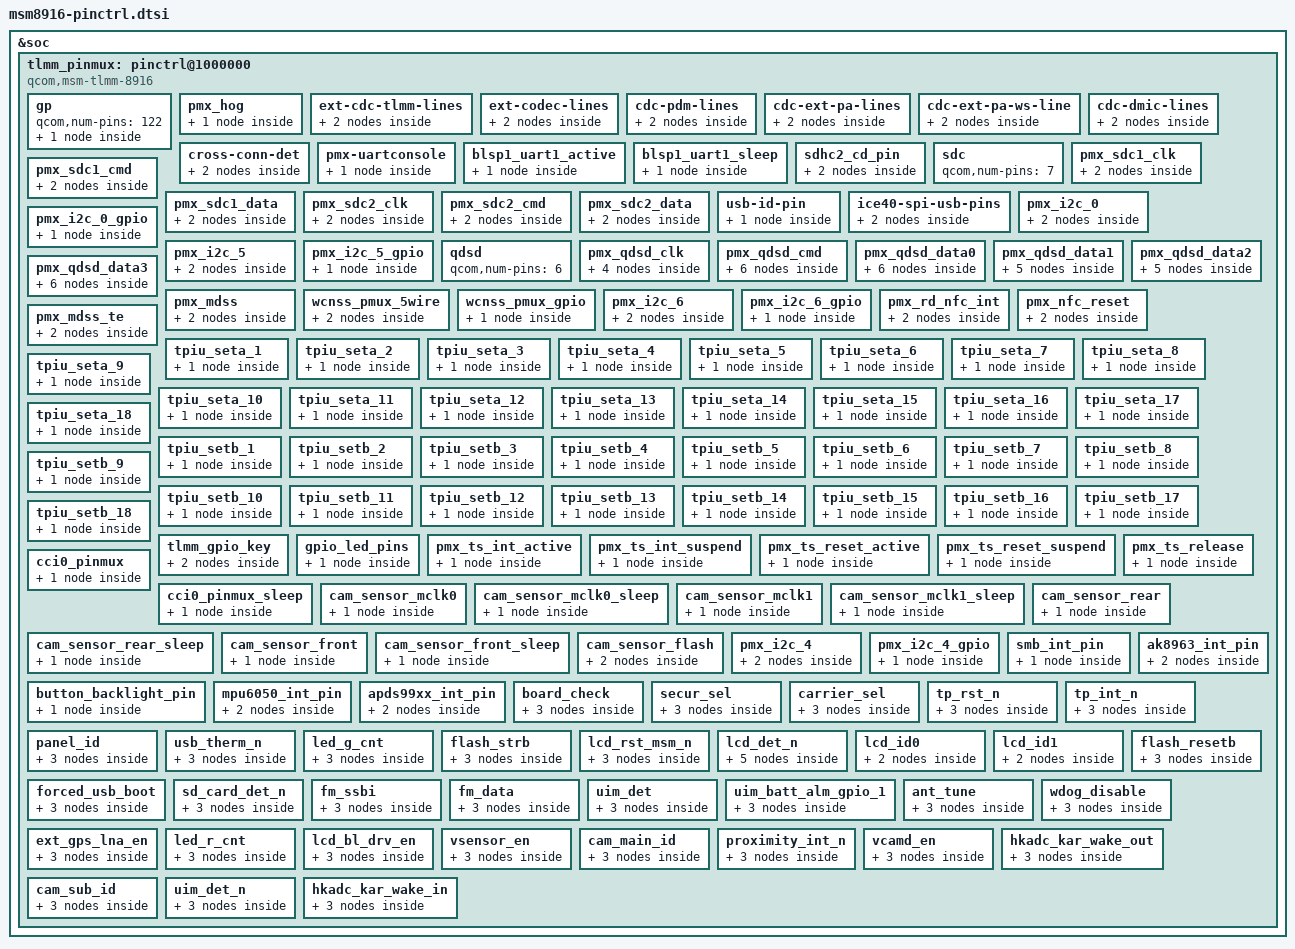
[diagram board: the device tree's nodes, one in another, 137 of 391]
/* Copyright (c) 2013-2014, The Linux Foundation. All rights reserved.
 *
 * This program is free software; you can redistribute it and/or modify
 * it under the terms of the GNU General Public License version 2 and
 * only version 2 as published by the Free Software Foundation.
 *
 * This program is distributed in the hope that it will be useful,
 * but WITHOUT ANY WARRANTY; without even the implied warranty of
 * MERCHANTABILITY or FITNESS FOR A PARTICULAR PURPOSE.  See the
 * GNU General Public License for more details.
 */
/*
 * This software is contributed or developed by KYOCERA Corporation.
 * (C) 2015 KYOCERA Corporation
 */

&soc {
	tlmm_pinmux: pinctrl@1000000 {
		compatible = "qcom,msm-tlmm-8916";
		reg = <0x1000000 0x300000>;
		interrupts = <0 208 0>;

		pinctrl-names = "default";
		pinctrl-0 = <&pmx_hog_default>;

		/*General purpose pins*/
		gp: gp {
			qcom,num-pins = <122>;
			#qcom,pin-cells = <1>;
			msm_gpio: msm_gpio {
				compatible = "qcom,msm-tlmm-gp";
				gpio-controller;
				#gpio-cells = <2>;
				interrupt-controller;
				#interrupt-cells = <2>;
				num_irqs = <122>;
			};
		};

		pmx_hog {
			qcom,pins = <&gp 2>, <&gp 3>, <&gp 10>, <&gp 11>, <&gp 34>,
						<&gp 49>, <&gp 50>, <&gp 51>, <&gp 52>,
						<&gp 53>, <&gp 54>, <&gp 55>, <&gp 56>,
						<&gp 74>, <&gp 75>, <&gp 76>, <&gp 77>, <&gp 78>,
						<&gp 81>, <&gp 82>, <&gp 83>, <&gp 84>, 
						<&gp 86>, <&gp 88>, <&gp 89>, <&gp 94>,
						<&gp 100>, <&gp 101>, <&gp 102>, <&gp 105>,
						<&gp 106>, <&gp 107>, <&gp 111>, <&gp 112>,
						<&gp 116>, <&gp 119>, <&gp 121>;
			qcom,num-grp-pins = <37>;
			qcom,pin-func = <0>;
			label = "hog";
			pmx_hog_default: pmx_hog_def {
				drive-strength = <2>;
				bias-pull-down;
				input-debounce = <0>;
			};
		};

		ext-cdc-tlmm-lines {
			qcom,pins = <&gp 116>, <&gp 112>, <&gp 117>,
						<&gp 118>, <&gp 119>;
			qcom,num-grp-pins = <5>;
			qcom,pin-func = <1>;
			label = "ext-cdc-tlmm-lines";
			ext_cdc_tlmm_lines_act: tlmm_lines_on {
				drive-strength = <8>;
				bias-pull-none;
			};
			ext_cdc_tlmm_lines_sus: tlmm_lines_off {
				drive-strength = <2>;
				bias-disable;
			};
		};

		ext-codec-lines {
			qcom,pins = <&gp 67>;
			qcom,num-grp-pins = <1>;
			qcom,pin-func = <0>;
			label = "ext-codec-lines";
			ext_codec_lines_act: lines_on {
				drive-strength = <8>;
				bias-disable;
				output-high;
			};
			ext_codec_lines_sus: lines_off {
				drive-strength = <2>;
				bias-disable;
			};
		};

		cdc-pdm-lines {
			qcom,pins = <&gp 63>, <&gp 64>, <&gp 65>,
					<&gp 66>, <&gp 67>, <&gp 68>;
			qcom,num-grp-pins = <6>;
			qcom,pin-func = <1>;
			label = "cdc-pdm-lines";
			cdc_pdm_lines_act: pdm_lines_on {
				drive-strength = <8>;
				bias-pull-none;
			};
			cdc_pdm_lines_sus: pdm_lines_off {
				drive-strength = <2>;
				bias-disable;
			};
		};

		cdc-ext-pa-lines {
			qcom,pins = <&gp 113>, <&gp 114>,
					<&gp 115>, <&gp 116>;
			qcom,num-grp-pins = <4>;
			qcom,pin-func = <1>;
			label = "cdc-ext-pa-lines";
			cdc_ext_pa_act: ext_pa_on {
				drive-strength = <8>;
				bias-pull-none;
			};
			cdc_ext_pa_sus: ext_pa_off {
				drive-strength = <2>;
				bias-disable;
			};
		};

		cdc-ext-pa-ws-line {
			qcom,pins = <&gp 110>;
			qcom,num-grp-pins = <1>;
			qcom,pin-func = <2>;
			label = "cdc-ext-pa-ws-line";
			cdc_ext_pa_ws_act: ext_pa_on {
				drive-strength = <8>;
				bias-pull-none;
			};
			cdc_ext_pa_ws_sus: ext_pa_off {
				drive-strength = <2>;
				bias-disable;
			};
		};

		cdc-dmic-lines {
			qcom,pins = <&gp 0>, <&gp 1>;
			qcom,num-grp-pins = <2>;
			qcom,pin-func = <4>;
			label = "cdc-dmic-lines";
			cdc_dmic_lines_act: dmic_lines_on {
				drive-strength = <8>;
			};
			cdc_dmic_lines_sus: dmic_lines_off {
				drive-strength = <2>;
				bias-disable;
			};
		};

		cross-conn-det {
			qcom,pins = <&gp 120>;
			qcom,num-grp-pins = <1>;
			qcom,pin-func = <0>;
			label = "cross-conn-det-sw";
			cross_conn_det_act: lines_on {
				drive-strength = <8>;
				output-low;
				bias-pull-down;
			};
			cross_conn_det_sus: lines_off {
				drive-strength = <2>;
				bias-disable;
			};
		};
		pmx-uartconsole {
			qcom,pins = <&gp 4>, <&gp 5>;
			qcom,num-grp-pins = <2>;
			qcom,pin-func = <2>;
			label = "uart-console";

		uart_console_sleep: uart-console {
				drive-strength = <2>;
				bias-pull-down;
			};
		};

		blsp1_uart1_active {
			qcom,pins = <&gp 0>, <&gp 1>, <&gp 2>, <&gp 3>;
			qcom,num-grp-pins = <4>;
			qcom,pin-func = <2>;
		        label = "blsp1_uart1_active";

			hsuart_active: default {
				drive-strength = <16>;
				bias-disable;
			};
		};

		blsp1_uart1_sleep {
			qcom,pins = <&gp 0>, <&gp 1>, <&gp 2>, <&gp 3>;
			qcom,num-grp-pins = <4>;
			qcom,pin-func = <0>;
		        label = "blsp1_uart1_sleep";

			hsuart_sleep: sleep {
				drive-strength = <2>;
				bias-disable;
			};
		};

		sdhc2_cd_pin {
			qcom,pins = <&gp 38>;
			qcom,num-grp-pins = <1>;
			qcom,pin-func = <0>;
			label = "cd-gpio";
			sdc2_cd_on: cd_on {
				drive-strength = <2>;
				bias-pull-up;
			};
			sdc2_cd_off: cd_off {
				drive-strength = <2>;
				bias-disable;
			};
		};

		/* SDC pin type */
		sdc: sdc {
			/* 0-2 for sdc1 4-6 for sdc2 */
			qcom,num-pins = <7>;
			/* Order of pins */
			/* SDC1: CLK -> 0, CMD -> 1, DATA -> 2 */
			/* SDC2: CLK -> 4, CMD -> 5, DATA -> 6 */
			#qcom,pin-cells = <1>;
		};

		pmx_sdc1_clk {
			qcom,pins = <&sdc 0>;
			qcom,num-grp-pins = <1>;
			label = "sdc1-clk";
			sdc1_clk_on: clk_on {
				bias-disable; /* NO pull */
				drive-strength = <16>; /* 16 MA */
			};
			sdc1_clk_off: clk_off {
				bias-disable; /* NO pull */
				drive-strength = <2>; /* 2 MA */
			};
		};

		pmx_sdc1_cmd {
			qcom,pins = <&sdc 1>;
			qcom,num-grp-pins = <1>;
			label = "sdc1-cmd";
			sdc1_cmd_on: cmd_on {
				bias-disable; /* NO pull */
				drive-strength = <8>; /* 8 MA */
			};
			sdc1_cmd_off: cmd_off {
				bias-pull-up; /* pull up */
				drive-strength = <2>; /* 2 MA */
			};
		};

		pmx_sdc1_data {
			qcom,pins = <&sdc 2>;
			qcom,num-grp-pins = <1>;
			label = "sdc1-data";
			sdc1_data_on: data_on {
				bias-pull-up; /* pull up */
				drive-strength = <8>; /* 8 MA */
			};
			sdc1_data_off: data_off {
				bias-pull-up; /* pull up */
				drive-strength = <2>; /* 2 MA */
			};
		};

		pmx_sdc2_clk {
			qcom,pins = <&sdc 4>;
			qcom,num-grp-pins = <1>;
			label = "sdc2-clk";
			sdc2_clk_on: clk_on {
				bias-disable; /* NO pull */
				drive-strength = <16>; /* 16 MA */
			};
			sdc2_clk_off: clk_off {
				bias-pull-down; /* pull down */
				drive-strength = <2>; /* 2 MA */
			};
		};

		pmx_sdc2_cmd {
			qcom,pins = <&sdc 5>;
			qcom,num-grp-pins = <1>;
			label = "sdc2-cmd";
			sdc2_cmd_on: cmd_on {
				bias-pull-up; /* pull up */
				drive-strength = <10>; /* 10 MA */
			};
			sdc2_cmd_off: cmd_off {
				bias-pull-down; /* pull down */
				drive-strength = <2>; /* 2 MA */
			};
		};

		pmx_sdc2_data {
			qcom,pins = <&sdc 6>;
			qcom,num-grp-pins = <1>;
			label = "sdc2-data";
			sdc2_data_on: data_on {
				bias-pull-up; /* pull up */
				drive-strength = <10>; /* 10 MA */
			};
			sdc2_data_off: data_off {
				bias-pull-down; /* pull down */
				drive-strength = <2>; /* 2 MA */
			};
		};

		usb-id-pin {
			qcom,pins = <&gp 110>;
			qcom,num-grp-pins = <1>;
			qcom,pin-func = <0>;
			label = "usb-id-pin";
			usbid_default: default {
				drive-strength = <8>;
				bias-pull-up;
			};
		};

		ice40-spi-usb-pins {
			qcom,pins = <&gp 0>, <&gp 1>, <&gp 3>, <&gp 114>;
			qcom,num-grp-pins = <4>;
			qcom,pin-func = <0>;
			label = "ice40-spi-usb-pins";

			/* active state */
			ice40_default: default {
				drive-strength = <8>;
				bias-disable;
			};

			/* sleep state */
			ice40_sleep: sleep {
				drive-strength = <2>;
				bias-pull-down;
			};
		};


		pmx_i2c_0 {
			/* CLK, DATA */
			qcom,pins = <&gp 7>, <&gp 6>;
			qcom,num-grp-pins = <2>;
			qcom,pin-func = <3>;
			label = "pmx_i2c_0";

			i2c_0_active: i2c_0_active {
				drive-strength = <2>; /* 2 MA */
				bias-disable;         /* No PULL */
			};

			i2c_0_sleep: i2c_0_sleep {
				drive-strength = <2>; /* 2 MA */
				bias-disable;	      /* No PULL */
			};
		};

		pmx_i2c_0_gpio {
			/* CLK, DATA */
			qcom,pins = <&gp 7>, <&gp 6>;
			qcom,num-grp-pins = <2>;
			qcom,pin-func = <0>;
			label = "pmx_i2c_0_gpio";

			i2c_0_gpio: i2c_0_gpio {
				drive-strength = <2>; /* 2 MA */
				bias-disable;         /* No PULL */
				input-debounce = <0>;
			};
		};

		pmx_i2c_5 {
			/* CLK, DATA */
			qcom,pins = <&gp 19>, <&gp 18>;
			qcom,num-grp-pins = <2>;
			qcom,pin-func = <2>;
			label = "pmx_i2c_5";

			i2c_5_active: i2c_5_active {
				drive-strength = <2>; /* 2 MA */
				bias-disable = <0>; /* No PULL */
			};

			i2c_5_sleep: i2c_5_sleep {
				drive-strength = <2>; /* 2 MA */
				bias-disable = <0>; /* No PULL */
			};
		};

		pmx_i2c_5_gpio {
			/* CLK, DATA */
			qcom,pins = <&gp 19>, <&gp 18>;
			qcom,num-grp-pins = <2>;
			qcom,pin-func = <0>;
			label = "pmx_i2c_5_gpio";

			i2c_5_gpio: i2c_5_gpio {
				drive-strength = <2>; /* 2 MA */
				bias-disable;         /* No PULL */
				input-debounce = <0>;
			};
		};

		/* QDSD pin type */
		qdsd: qdsd {
			/* 0-> clk, 1 -> cmd, 2->data0, 3->data1, 4->data2, 5->data3 */
			qcom,num-pins = <6>;

			#qcom,pin-cells = <1>;
		};

		pmx_qdsd_clk {
			qcom,pins = <&qdsd 0>;
			qcom,num-grp-pins = <1>;
			label = "qdsd-clk";
			qdsd_clk_sdcard: clk_sdcard {
				bias-disable; /* NO pull */
				drive-strength = <7>; /* 7 MA */
			};
			qdsd_clk_trace: clk_trace {
				bias-pull-down; /* pull down */
				drive-strength = <0>; /* 0 MA */
			};
			qdsd_clk_swdtrc: clk_swdtrc {
				bias-pull-down; /* pull down */
				drive-strength = <0>; /* 0 MA */
			};
			qdsd_clk_spmi: clk_spmi {
				bias-pull-down; /* pull down */
				drive-strength = <0>; /* 0 MA */
			};
		};

		pmx_qdsd_cmd {
			qcom,pins = <&qdsd 1>;
			qcom,num-grp-pins = <1>;
			label = "qdsd-cmd";
			qdsd_cmd_sdcard: cmd_sdcard {
				bias-pull-down; /* pull down */
				drive-strength = <3>; /* 3 MA */
			};
			qdsd_cmd_trace: cmd_trace {
				bias-pull-down; /* pull down */
				drive-strength = <0>; /* 0 MA */
			};
			qdsd_cmd_swduart: cmd_uart {
				bias-pull-up; /* pull up */
				drive-strength = <0>; /* 0 MA */
			};
			qdsd_cmd_swdtrc: cmd_swdtrc {
				bias-pull-up; /* pull up */
				drive-strength = <0>; /* 0 MA */
			};
			qdsd_cmd_jtag: cmd_jtag {
				bias-disable; /* NO pull */
				drive-strength = <3>; /* 3 MA */
			};
			qdsd_cmd_spmi: cmd_spmi {
				bias-pull-down; /* pull down */
				drive-strength = <4>; /* 4 MA */
			};
		};

		pmx_qdsd_data0 {
			qcom,pins = <&qdsd 2>;
			qcom,num-grp-pins = <1>;
			label = "qdsd-data0";
			qdsd_data0_sdcard: data0_sdcard {
				bias-pull-down; /* pull down */
				drive-strength = <3>; /* 3 MA */
			};
			qdsd_data0_trace: data0_trace {
				bias-pull-down; /* pull down */
				drive-strength = <0>; /* 0 MA */
			};
			qdsd_data0_swduart: data0_uart {
				bias-pull-down; /* pull down */
				drive-strength = <0>; /* 0 MA */
			};
			qdsd_data0_swdtrc: data0_swdtrc {
				bias-pull-down; /* pull down */
				drive-strength = <0>; /* 0 MA */
			};
			qdsd_data0_jtag: data0_jtag {
				bias-pull-up; /* pull up */
				drive-strength = <0>; /* 0 MA */
			};
			qdsd_data0_spmi: data0_spmi {
				bias-pull-down; /* pull down */
				drive-strength = <0>; /* 0 MA */
			};
		};

		pmx_qdsd_data1 {
			qcom,pins = <&qdsd 3>;
			qcom,num-grp-pins = <1>;
			label = "qdsd-data1";
			qdsd_data1_sdcard: data1_sdcard {
				bias-pull-down; /* pull down */
				drive-strength = <3>; /* 3 MA */
			};
			qdsd_data1_trace: data1_trace {
				bias-pull-down; /* pull down */
				drive-strength = <0>; /* 0 MA */
			};
			qdsd_data1_swduart: data1_uart {
				bias-pull-down; /* pull down */
				drive-strength = <0>; /* 0 MA */
			};
			qdsd_data1_swdtrc: data1_swdtrc {
				bias-pull-down; /* pull down */
				drive-strength = <0>; /* 0 MA */
			};
			qdsd_data1_jtag: data1_jtag {
				bias-pull-down; /* pull down */
				drive-strength = <0>; /* 0 MA */
			};
		};

		pmx_qdsd_data2 {
			qcom,pins = <&qdsd 4>;
			qcom,num-grp-pins = <1>;
			label = "qdsd-data2";
			qdsd_data2_sdcard: data2_sdcard {
				bias-pull-down; /* pull down */
				drive-strength = <3>; /* 3 MA */
			};
			qdsd_data2_trace: data2_trace {
				bias-pull-down; /* pull down */
				drive-strength = <0>; /* 0 MA */
			};
			qdsd_data2_swduart: data2_uart {
				bias-pull-down; /* pull down */
				drive-strength = <0>; /* 0 MA */
			};
			qdsd_data2_swdtrc: data2_swdtrc {
				bias-pull-down; /* pull down */
				drive-strength = <0>; /* 0 MA */
			};
			qdsd_data2_jtag: data2_jtag {
				bias-pull-up; /* pull up */
				drive-strength = <3>; /* 3 MA */
			};
		};

		pmx_qdsd_data3 {
			qcom,pins = <&qdsd 5>;
			qcom,num-grp-pins = <1>;
			label = "qdsd-data3";
			qdsd_data3_sdcard: data3_sdcard {
				bias-pull-down; /* pull down */
				drive-strength = <3>; /* 3 MA */
			};
			qdsd_data3_trace: data3_trace {
				bias-pull-down; /* pull down */
				drive-strength = <0>; /* 0 MA */
			};
			qdsd_data3_swduart: data3_uart {
				bias-pull-up; /* pull up */
				drive-strength = <0>; /* 0 MA */
			};
			qdsd_data3_swdtrc: data3_swdtrc {
				bias-pull-up; /* pull up */
				drive-strength = <0>; /* 0 MA */
			};
			qdsd_data3_jtag: data3_jtag {
				bias-pull-up; /* pull up */
				drive-strength = <0>; /* 0 MA */
			};
			qdsd_data3_spmi: data3_spmi {
				bias-pull-down; /* pull down */
				drive-strength = <3>; /* 3 MA */
			};
		};

		pmx_mdss: pmx_mdss {
			label = "mdss-pins";
			qcom,pin-func = <0>;
			mdss_dsi_active: active {
				drive-strength = <8>; /* 8 mA */
				bias-disable = <0>; /* no pull */
				output-high;
			};
			mdss_dsi_suspend: suspend {
				drive-strength = <2>; /* 2 mA */
				bias-pull-down; /* pull down */
				output-low;
			};
		};

		wcnss_pmux_5wire: wcnss_pmux_5wire {
			/* Uses general purpose pins */
			qcom,pins = <&gp 40>, <&gp 41>,
				    <&gp 42>, <&gp 43>,
				    <&gp 44>;
			qcom,num-grp-pins = <5>;
			qcom,pin-func = <1>;
			label = "wcnss_5wire_pins";
			/* Active configuration of bus pins */
			wcnss_default: wcnss_default {
			        drive-strength = <6>; /* 6 MA */
			        bias-pull-up; /* PULL UP */
			};
			wcnss_sleep: wcnss_sleep {
			        drive-strength = <2>; /* 2 MA */
			        bias-pull-down; /* PULL Down */
			};
		};

		wcnss_pmux_gpio: wcnss_pmux_gpio {
			/* Uses general purpose pins */
			qcom,pins = <&gp 40>, <&gp 41>,
				    <&gp 42>, <&gp 43>,
				    <&gp 44>;
			qcom,num-grp-pins = <5>;
			qcom,pin-func = <0>;
			label = "wcnss_5gpio_pins";
			/* Active configuration of bus pins */
			wcnss_gpio_default: wcnss_gpio_default {
			        drive-strength = <6>; /* 6 MA */
			        bias-pull-up; /* PULL UP */
			};
		};

		pmx_i2c_6 {
			/* CLK, DATA */
			qcom,pins = <&gp 22>, <&gp 23>;
			qcom,num-grp-pins = <2>;
			qcom,pin-func = <2>;
			label = "pmx_i2c_6";
			/* active state */
			i2c_6_active: i2c_6_active{
				drive-strength = <2>; /* 2 MA */
				bias-disable; /* No PULL */
			};
			/*suspended state */
			i2c_6_sleep: i2c_6_sleep {
				drive-strength = <2>; /* 2 MA */
				bias-disable; /* No PULL */
			};
		};

		pmx_i2c_6_gpio {
			/* CLK, DATA */
			qcom,pins = <&gp 22>, <&gp 23>;
			qcom,num-grp-pins = <2>;
			qcom,pin-func = <0>;
			label = "pmx_i2c_6_gpio";

			i2c_6_gpio: i2c_6_gpio {
				drive-strength = <2>; /* 2 MA */
				bias-disable;         /* No PULL */
				input-debounce = <0>;
			};
		};

		pmx_rd_nfc_int{
			qcom,pins = <&gp 21>;
			qcom,pin-func = <0>;
			qcom,num-grp-pins = <1>;
			label = "pmx_nfc_int";

			nfc_int_active: active {
				drive-strength = <6>;
				bias-pull-up;
			};

			nfc_int_suspend: suspend {
				drive-strength = <6>;
				bias-pull-up;
			};
		};

		pmx_nfc_reset{
			qcom,pins = <&gp 20>;
			qcom,pin-func = <0>;
			qcom,num-grp-pins = <1>;
			label = "pmx_nfc_disable";

			nfc_disable_active: active {
				drive-strength = <6>;
				bias-pull-up;
			};

			nfc_disable_suspend: suspend {
				drive-strength = <6>;
				bias-disable;
			};
		};

		pmx_mdss_te: pmx_mdss_te {
			label = "mdss-te-pin";
			qcom,pin-func = <1>;
			mdss_te_active: active {
				drive-strength = <2>; /* 2 mA */
				bias-pull-down; /* pull down */
				input-debounce = <0>;
			};
			mdss_te_suspend: suspend {
				drive-strength = <2>; /* 2 mA */
				bias-pull-down; /* pull down */
				input-debounce = <0>;
			};
		};

		/* CoreSight */
		tpiu_seta_1 {
			qcom,pins = <&gp 8>;
			qcom,num-grp-pins = <1>;
			qcom,pin-func = <3>;
			label = "tpiu-seta-1";
			seta_1: seta {
				drive-strength = <16>;
				bias-disable;
			};
		};

		tpiu_seta_2 {
			qcom,pins = <&gp 9>;
			qcom,num-grp-pins = <1>;
			qcom,pin-func = <2>;
			label = "tpiu-seta-2";
			seta_2: seta {
				drive-strength = <16>;
				bias-disable;
			};
		};

		tpiu_seta_3 {
			qcom,pins = <&gp 10>;
			qcom,num-grp-pins = <1>;
			qcom,pin-func = <3>;
			label = "tpiu-seta-3";
			seta_3: seta {
				drive-strength = <16>;
				bias-disable;
			};
		};

		tpiu_seta_4 {
			qcom,pins = <&gp 39>;
			qcom,num-grp-pins = <1>;
			qcom,pin-func = <2>;
			label = "tpiu-seta-4";
			seta_4: seta {
				drive-strength = <16>;
				bias-disable;
			};
		};

		tpiu_seta_5 {
			qcom,pins = <&gp 40>;
			qcom,num-grp-pins = <1>;
			qcom,pin-func = <2>;
			label = "tpiu-seta-5";
			seta_5: seta {
				drive-strength = <16>;
				bias-disable;
			};
		};

		tpiu_seta_6 {
			qcom,pins = <&gp 41>;
			qcom,num-grp-pins = <1>;
			qcom,pin-func = <2>;
			label = "tpiu-seta-6";
			seta_6: seta {
				drive-strength = <16>;
				bias-disable;
			};
		};

		tpiu_seta_7 {
			qcom,pins = <&gp 42>;
			qcom,num-grp-pins = <1>;
			qcom,pin-func = <2>;
			label = "tpiu-seta-7";
			seta_7: seta {
				drive-strength = <16>;
				bias-disable;
			};
		};

		tpiu_seta_8 {
			qcom,pins = <&gp 43>;
			qcom,num-grp-pins = <1>;
			qcom,pin-func = <3>;
			label = "tpiu-seta-8";
			seta_8: seta {
				drive-strength = <16>;
				bias-disable;
			};
		};

		tpiu_seta_9 {
			qcom,pins = <&gp 45>;
			qcom,num-grp-pins = <1>;
			qcom,pin-func = <3>;
			label = "tpiu-seta-9";
			seta_9: seta {
				drive-strength = <16>;
				bias-disable;
			};
		};

		tpiu_seta_10 {
			qcom,pins = <&gp 46>;
			qcom,num-grp-pins = <1>;
			qcom,pin-func = <2>;
			label = "tpiu-seta-10";
			seta_10: seta {
				drive-strength = <16>;
				bias-disable;
			};
		};

		tpiu_seta_11 {
			qcom,pins = <&gp 47>;
			qcom,num-grp-pins = <1>;
			qcom,pin-func = <3>;
			label = "tpiu-seta-11";
			seta_11: seta {
				drive-strength = <16>;
				bias-disable;
			};
		};

		tpiu_seta_12 {
			qcom,pins = <&gp 48>;
			qcom,num-grp-pins = <1>;
			qcom,pin-func = <2>;
			label = "tpiu-seta-12";
			seta_12: seta {
				drive-strength = <16>;
				bias-disable;
			};
		};

		tpiu_seta_13 {
			qcom,pins = <&gp 62>;
			qcom,num-grp-pins = <1>;
			qcom,pin-func = <2>;
			label = "tpiu-seta-13";
			seta_13: seta {
				drive-strength = <16>;
				bias-disable;
			};
		};

		tpiu_seta_14 {
			qcom,pins = <&gp 69>;
			qcom,num-grp-pins = <1>;
			qcom,pin-func = <2>;
			label = "tpiu-seta-14";
			seta_14: seta {
				drive-strength = <16>;
				bias-disable;
			};
		};

		tpiu_seta_15 {
			qcom,pins = <&gp 112>;
			qcom,num-grp-pins = <1>;
			qcom,pin-func = <5>;
			label = "tpiu-seta-15";
			seta_15: seta {
				drive-strength = <16>;
				bias-disable;
			};
		};

		tpiu_seta_16 {
			qcom,pins = <&gp 113>;
			qcom,num-grp-pins = <1>;
			qcom,pin-func = <9>;
			label = "tpiu-seta-16";
			seta_16: seta {
				drive-strength = <16>;
				bias-disable;
			};
		};

		tpiu_seta_17 {
			qcom,pins = <&gp 114>;
			qcom,num-grp-pins = <1>;
			qcom,pin-func = <8>;
			label = "tpiu-seta-17";
			seta_17: seta {
				drive-strength = <16>;
				bias-disable;
			};
		};

		tpiu_seta_18 {
			qcom,pins = <&gp 115>;
			qcom,num-grp-pins = <1>;
			qcom,pin-func = <8>;
			label = "tpiu-seta-18";
			seta_18: seta {
				drive-strength = <16>;
				bias-disable;
			};
		};

		tpiu_setb_1 {
			qcom,pins = <&gp 4>;
			qcom,num-grp-pins = <1>;
			qcom,pin-func = <5>;
			label = "tpiu-setb-1";
			setb_1: setb {
				drive-strength = <16>;
				bias-disable;
			};
		};

		tpiu_setb_2 {
			qcom,pins = <&gp 5>;
			qcom,num-grp-pins = <1>;
			qcom,pin-func = <5>;
			label = "tpiu-setb-2";
			setb_2: setb {
				drive-strength = <16>;
				bias-disable;
			};
		};

		tpiu_setb_3 {
			qcom,pins = <&gp 26>;
			qcom,num-grp-pins = <1>;
			qcom,pin-func = <7>;
			label = "tpiu-setb-3";
			setb_3: setb {
				drive-strength = <16>;
				bias-disable;
			};
		};

		tpiu_setb_4 {
			qcom,pins = <&gp 27>;
			qcom,num-grp-pins = <1>;
			qcom,pin-func = <9>;
			label = "tpiu-setb-4";
			setb_4: setb {
				drive-strength = <16>;
				bias-disable;
			};
		};

		tpiu_setb_5 {
			qcom,pins = <&gp 28>;
			qcom,num-grp-pins = <1>;
			qcom,pin-func = <7>;
			label = "tpiu-setb-5";
			setb_5: setb {
				drive-strength = <16>;
				bias-disable;
			};
		};

		tpiu_setb_6 {
			qcom,pins = <&gp 29>;
			qcom,num-grp-pins = <1>;
			qcom,pin-func = <7>;
			label = "tpiu-setb-6";
			setb_6: setb {
				drive-strength = <16>;
				bias-disable;
			};
		};

		tpiu_setb_7 {
			qcom,pins = <&gp 30>;
			qcom,num-grp-pins = <1>;
			qcom,pin-func = <9>;
			label = "tpiu-setb-7";
			setb_7: setb {
				drive-strength = <16>;
				bias-disable;
			};
		};

		tpiu_setb_8 {
			qcom,pins = <&gp 31>;
			qcom,num-grp-pins = <1>;
			qcom,pin-func = <10>;
			label = "tpiu-setb-8";
			setb_8: setb {
				drive-strength = <16>;
				bias-disable;
			};
		};

		tpiu_setb_9 {
			qcom,pins = <&gp 32>;
			qcom,num-grp-pins = <1>;
			qcom,pin-func = <10>;
			label = "tpiu-setb-9";
			setb_9: setb {
				drive-strength = <16>;
				bias-disable;
			};
		};

		tpiu_setb_10 {
			qcom,pins = <&gp 33>;
			qcom,num-grp-pins = <1>;
			qcom,pin-func = <9>;
			label = "tpiu-setb-10";
			setb_10: setb {
				drive-strength = <16>;
				bias-disable;
			};
		};

		tpiu_setb_11 {
			qcom,pins = <&gp 34>;
			qcom,num-grp-pins = <1>;
			qcom,pin-func = <9>;
			label = "tpiu-setb-11";
			setb_11: setb {
				drive-strength = <16>;
				bias-disable;
			};
		};

		tpiu_setb_12 {
			qcom,pins = <&gp 35>;
			qcom,num-grp-pins = <1>;
			qcom,pin-func = <9>;
			label = "tpiu-setb-12";
			setb_12: setb {
				drive-strength = <16>;
				bias-disable;
			};
		};

		tpiu_setb_13 {
			qcom,pins = <&gp 36>;
			qcom,num-grp-pins = <1>;
			qcom,pin-func = <8>;
			label = "tpiu-setb-13";
			setb_13: setb {
				drive-strength = <16>;
				bias-disable;
			};
		};

		tpiu_setb_14 {
			qcom,pins = <&gp 37>;
			qcom,num-grp-pins = <1>;
			qcom,pin-func = <7>;
			label = "tpiu-setb-14";
			setb_14: setb {
				drive-strength = <16>;
				bias-disable;
			};
		};

		tpiu_setb_15 {
			qcom,pins = <&gp 110>;
			qcom,num-grp-pins = <1>;
			qcom,pin-func = <4>;
			label = "tpiu-setb-15";
			setb_15: setb {
				drive-strength = <16>;
				bias-disable;
			};
		};

		tpiu_setb_16 {
			qcom,pins = <&gp 111>;
			qcom,num-grp-pins = <1>;
			qcom,pin-func = <1>;
			label = "tpiu-setb-16";
			setb_16: setb {
				drive-strength = <16>;
				bias-disable;
			};
		};

		tpiu_setb_17 {
			qcom,pins = <&gp 120>;
			qcom,num-grp-pins = <1>;
			qcom,pin-func = <10>;
			label = "tpiu-setb-17";
			setb_17: setb {
				drive-strength = <16>;
				bias-disable;
			};
		};

		tpiu_setb_18 {
			qcom,pins = <&gp 121>;
			qcom,num-grp-pins = <1>;
			qcom,pin-func = <11>;
			label = "tpiu-setb-18";
			setb_18: setb {
				drive-strength = <16>;
				bias-disable;
			};
		};

		tlmm_gpio_key {
			qcom,pins = <&gp 108>;
			qcom,pin-func = <0>;
			qcom,num-grp-pins = <1>;
			label = "tlmm_gpio_key";
			gpio_key_active: gpio_key_active {
				drive-strength = <2>;
				bias-pull-up;
			};
			gpio_key_suspend: gpio_key_suspend {
				drive-strength = <2>;
				bias-pull-up;
			};
		};

		gpio_led_pins {
			qcom,pins = <&gp 8>, <&gp 9>, <&gp 10>;
			qcom,num-grp-pins = <3>;
			label = "gpio-led-pins";
			gpio_led_off: led_off {
				drive-strength = <2>;
				bias-disable;
				output-low;
			};
		};

		/* add pingrp for touchscreen */
		pmx_ts_int_active {
			qcom,pins = <&gp 13>;
			qcom,pin-func = <0>;
			qcom,num-grp-pins = <1>;
			label = "pmx_ts_int_active";

			ts_int_active: ts_int_active {
				drive-strength = <16>;
				bias-pull-up;
			};
		};

		pmx_ts_int_suspend {
			qcom,pins = <&gp 13>;
			qcom,pin-func = <0>;
			qcom,num-grp-pins = <1>;
			label = "pmx_ts_int_suspend";

			ts_int_suspend: ts_int_suspend {
				drive-strength = <2>;
				bias-pull-down;
			};
		};

		pmx_ts_reset_active {
			qcom,pins = <&gp 12>;
			qcom,pin-func = <0>;
			qcom,num-grp-pins = <1>;
			label = "pmx_ts_reset_active";

			ts_reset_active: ts_reset_active {
				drive-strength = <16>;
				bias-pull-up;
			};
		};

		pmx_ts_reset_suspend {
			qcom,pins = <&gp 12>;
			qcom,pin-func = <0>;
			qcom,num-grp-pins = <1>;
			label = "pmx_ts_reset_suspend";

			ts_reset_suspend: ts_reset_suspend {
				drive-strength = <2>;
				bias-pull-down;
			};
		};

		pmx_ts_release {
			qcom,pins = <&gp 13>, <&gp 12>;
			qcom,num-grp-pins = <2>;
			label = "pmx_ts_release";

			ts_release: ts_release {
				drive-strength = <2>;
				bias-pull-down;
			};
		};

		cci0_pinmux {
			/* CLK, DATA */
			qcom,pins = <&gp 29>, <&gp 30>;
			qcom,num-grp-pins = <2>;
			qcom,pin-func = <1>;
			label = "cci0";
			/* active state */
			cci0_default: default {
				drive-strength = <2>; /* 2 MA */
				bias-disable = <0>; /* No PULL */
			};
		};

		cci0_pinmux_sleep {
			/* CLK, DATA */
			qcom,pins = <&gp 29>, <&gp 30>;
			qcom,num-grp-pins = <2>;
			qcom,pin-func = <0>; /* 0 */
			label = "cci0-sleep";
			/*suspended state */
			cci0_sleep: sleep {
				drive-strength = <2>; /* 2 MA */
				bias-pull-down; /* PULL DOWN */
			};
		};

		cam_sensor_mclk0 {
			/* MCLK */
			qcom,pins = <&gp 26>;
			qcom,num-grp-pins = <1>;
			qcom,pin-func = <1>;
			label = "cam-sensor-mclk0";
			/* active state */
			cam_sensor_mclk0_default: default {
				drive-strength = <4>; /* 4 MA */
				bias-disable = <0>; /* No PULL */
			};
		};

		cam_sensor_mclk0_sleep {
			/* MCLK */
			qcom,pins = <&gp 26>;
			qcom,num-grp-pins = <1>;
			label = "cam-sensor-mclk0-sleep";
			/* suspend state */
			cam_sensor_mclk0_sleep: sleep {
				drive-strength = <4>; /* 4 MA */
				bias-disable; /* No PULL */
			};
		};

		cam_sensor_mclk1 {
			/* MCLK */
			qcom,pins = <&gp 27>;
			qcom,num-grp-pins = <1>;
			qcom,pin-func = <1>;
			label = "cam-sensor-mclk1";
			/* active state */
			cam_sensor_mclk1_default: default {
				drive-strength = <4>; /* 4 MA */
				bias-disable = <0>; /* No PULL */
			};
		};

		cam_sensor_mclk1_sleep {
			/* MCLK */
			qcom,pins = <&gp 27>;
			qcom,num-grp-pins = <1>;
			label = "cam-sensor-mclk1-sleep";
			/* suspend state */
			cam_sensor_mclk1_sleep: sleep {
				drive-strength = <4>; /* 4 MA */
				bias-disable; /* No PULL */
			};
		};

		cam_sensor_rear {
			/* RESET, STANDBY */
			qcom,pins =  <&gp 35>;
			qcom,num-grp-pins = <1>;
			qcom,pin-func = <0>;
			label = "cam-sensor-rear";
			/* active state */
			cam_sensor_rear_default: default {
				drive-strength = <2>; /* 2 MA */
				bias-disable = <0>; /* No PULL */
			};
		};

		cam_sensor_rear_sleep {
			/* RESET, STANDBY */
			qcom,pins =  <&gp 35>;
			qcom,num-grp-pins = <1>;
			qcom,pin-func = <0>;
			label = "cam-sensor-rear-sleep";
			/*suspended state */
			cam_sensor_rear_sleep: sleep {
				drive-strength = <2>; /* 2 MA */
				bias-disable; /* No PULL */
			};
		};

		cam_sensor_front {
			/* RESET, STANDBY */
			qcom,pins = <&gp 28>;
			qcom,num-grp-pins = <1>;
			qcom,pin-func = <0>;
			label = "cam_sensor_front";
			/* active state */
			cam_sensor_front_default: default {
				drive-strength = <2>; /* 2 MA */
				bias-disable = <0>; /* No PULL */
			};
		};

		cam_sensor_front_sleep {
			/* RESET, STANDBY */
			qcom,pins = <&gp 28>;
			qcom,num-grp-pins = <1>;
			qcom,pin-func = <0>;
			label = "cam-sensor-front-sleep";
			/*suspended state */
			cam_sensor_front_sleep: sleep {
				drive-strength = <2>; /* 2 MA */
				bias-disable; /* No PULL */
			};
		};

		cam_sensor_flash {
			/* FLSH_RESET,FLASH_EN,FLASH_NOW */
			qcom,pins = <&gp 36>, <&gp 24>,<&gp 32> ;
			qcom,num-grp-pins = <3>;
			qcom,pin-func = <0>;
			label = "cam_sensor_flash";
			/* active state */
			cam_sensor_flash_default: default {
				drive-strength = <2>; /* 2 MA */
				bias-disable = <0>; /* No PULL */
			};
			/*suspended state */
			cam_sensor_flash_sleep: sleep {
				drive-strength = <2>; /* 2 MA */
				bias-pull-down = <0>; /* PULL DOWN */
			};
		};

		pmx_i2c_4 {
			/* CLK, DATA */
			qcom,pins = <&gp 14>, <&gp 15>;
			qcom,num-grp-pins = <2>;
			qcom,pin-func = <2>;
			label = "pmx_i2c_4";

			i2c_4_active: i2c_4_active {
				drive-strength = <2>;	/* 2 MA */
				bias-disable = <0>;	/* No PULL */
			};

			i2c_4_sleep: i2c_4_sleep {
				drive-strength = <2>;	/* 2 MA */
				bias-disable = <0>;	/* No PULL */
			};

		};

		pmx_i2c_4_gpio {
			/* CLK, DATA */
			qcom,pins = <&gp 14>, <&gp 15>;
			qcom,num-grp-pins = <2>;
			qcom,pin-func = <0>;
			label = "pmx_i2c_4_gpio";

			i2c_4_gpio: i2c_4_gpio {
				drive-strength = <2>; /* 2 MA */
				bias-disable;         /* No PULL */
				input-debounce = <0>;
			};
		};

		smb_int_pin {
			qcom,pins = <&gp 62>;
			qcom,num-grp-pins = <1>;
			qcom,pin-func = <0>;
			label = "smb1360_int_gpio";
			smb_int_default: smb_int_default {
				drive-strength = <2>;	/* 2 MA */
				bias-pull-up;		/* PULL UP*/
			};
		};

		button_backlight_pin {
			qcom,pins = <&gp 119>;
			qcom,num-grp-pins = <1>;
			qcom,pin-func = <0>;
			label = "button-backlight-pin";
			button_backlight_off: button_backlight_off {
				drive-strength = <2>;
				bias-disable;
				output-low;
			};
		};

		mpu6050_int_pin {
			qcom,pins = <&gp 115>;
			qcom,pin-func = <0>;
			qcom,num-grp-pins = <1>;
			label = "mpu6050-irq";
			mpu6050_default: mpu6050_default {
				drive-strength = <6>;
				bias-pull-up;
			};
			mpu6050_sleep: mpu6050_sleep {
				drive-strength = <2>;
			};
		};

		apds99xx_int_pin {
			qcom,pins = <&gp 113>;
			qcom,pin-func = <0>;
			qcom,num-grp-pins = <1>;
			label = "apds99xx-irq";
			apds99xx_default: apds99xx_default {
				drive-strength = <6>;
				bias-pull-up;
			};
			apds99xx_sleep: apds99xx_sleep {
				drive-strength = <2>;
				bias-pull-down;
			};
		};
		ak8963_int_pin {
			qcom,pins = <&gp 69>;
			qcom,pin-func = <0>;
			qcom,num-grp-pins = <1>;
			label = "ak8963-irq";
			ak8963_default: ak8963_default {
				drive-strength = <6>;
				bias-pull-up;
			};
			ak8963_sleep: ak8963_sleep {
				drive-strength = <2>;
				bias-pull-down;
			};
		};

		board_check {
			qcom,pins = <&gp 0>, <&gp 1>, <&gp 4>;
			qcom,pin-func = <0>;
			qcom,num-grp-pins = <3>;
			label = "board_check";
			board_check_default: board_check_default {
				drive-strength = <2>;
				bias-pull-down;
				input-debounce = <0>;
			};
			board_check_active: board_check_active {
				drive-strength = <2>;
				bias-pull-down;
				input-debounce = <0>;
			};
			board_check_suspend: board_check_suspend {
				drive-strength = <2>;
				bias-pull-down;
				input-debounce = <0>;
			};
		};

		secur_sel {
			qcom,pins = <&gp 5>;
			qcom,pin-func = <0>;
			qcom,num-grp-pins = <1>;
			label = "secur_sel";
			secur_sel_default: secur_sel_default {
				drive-strength = <2>;
				bias-pull-down;
				input-debounce = <0>;
			};
			secur_sel_active: secur_sel_active {
				drive-strength = <2>;
				bias-pull-down;
				input-debounce = <0>;
			};
			secur_sel_suspend: secur_sel_suspend {
				drive-strength = <2>;
				bias-pull-down;
				input-debounce = <0>;
			};
		};

		carrier_sel {
			qcom,pins = <&gp 8>, <&gp 9>, <&gp 17>;
			qcom,pin-func = <0>;
			qcom,num-grp-pins = <3>;
			label = "carrier_sel";
			carrier_sel_default: carrier_sel_default {
				drive-strength = <2>;
				bias-pull-down;
				input-debounce = <0>;
			};
			carrier_sel_active: carrier_sel_active {
				drive-strength = <2>;
				bias-pull-down;
				input-debounce = <0>;
			};
			carrier_sel_suspend: carrier_sel_suspend {
				drive-strength = <2>;
				bias-pull-down;
				input-debounce = <0>;
			};
		};

		tp_rst_n {
			qcom,pins = <&gp 12>;
			qcom,pin-func = <0>;
			qcom,num-grp-pins = <1>;
			label = "tp_rst_n";
			tp_rst_n_default: tp_rst_n_default {
				drive-strength = <2>;
				bias-disable;
				output-low;
			};
			tp_rst_n_active: tp_rst_n_active {
				drive-strength = <2>;
				bias-disable;
				output-low;
			};
			tp_rst_n_suspend: tp_rst_n_suspend {
				drive-strength = <2>;
				bias-disable;
				output-low;
			};
		};

		tp_int_n {
			qcom,pins = <&gp 13>;
			qcom,pin-func = <0>;
			qcom,num-grp-pins = <1>;
			label = "tp_int_n";
			tp_int_n_default: tp_int_n_default {
				drive-strength = <2>;
				bias-disable;
				input-debounce = <0>;
			};
			tp_int_n_active: tp_int_n_active {
				drive-strength = <2>;
				bias-disable;
				input-debounce = <0>;
			};
			tp_int_n_suspend: tp_int_n_suspend {
				drive-strength = <2>;
				bias-disable;
				input-debounce = <0>;
			};
		};

		panel_id {
			qcom,pins = <&gp 16>;
			qcom,pin-func = <0>;
			qcom,num-grp-pins = <1>;
			label = "panel_id";
			panel_id_default: panel_id_default {
				drive-strength = <2>;
				bias-pull-up;
				input-debounce = <0>;
			};
			panel_id_active: panel_id_active {
				drive-strength = <2>;
				bias-pull-down;
				input-debounce = <0>;
			};
			panel_id_suspend: panel_id_suspend {
				drive-strength = <2>;
				bias-pull-down;
				input-debounce = <0>;
			};
		};

		usb_therm_n {
			qcom,pins = <&gp 20>;
			qcom,pin-func = <0>;
			qcom,num-grp-pins = <1>;
			label = "usb_therm_n";
			usb_therm_n_default: usb_therm_n_default {
				drive-strength = <2>;
				bias-pull-up;
				input-debounce = <0>;
			};
			usb_therm_n_active: usb_therm_n_active {
				drive-strength = <2>;
				bias-pull-up;
				input-debounce = <0>;
			};
			usb_therm_n_suspend: usb_therm_n_suspend {
				drive-strength = <2>;
				bias-pull-up;
				input-debounce = <0>;
			};
		};

		led_g_cnt {
			qcom,pins = <&gp 21>;
			qcom,pin-func = <0>;
			qcom,num-grp-pins = <1>;
			label = "led_g_cnt";
			led_g_cnt_default: led_g_cnt_default {
				drive-strength = <2>;
				bias-disable;
				output-low;
			};
			led_g_cnt_active: led_g_cnt_active {
				drive-strength = <2>;
				bias-disable;
				output-low;
			};
			led_g_cnt_suspend: led_g_cnt_suspend {
				drive-strength = <2>;
				bias-disable;
				output-low;
			};
		};

		flash_strb {
			qcom,pins = <&gp 24>, <&gp 32>;
			qcom,pin-func = <0>;
			qcom,num-grp-pins = <2>;
			label = "flash_strb";
			flash_strb_default: flash_strb_default {
				drive-strength = <2>;
				bias-disable;
				output-low;
			};
			flash_strb_active: flash_strb_active {
				drive-strength = <2>;
				bias-disable;
				output-low;
			};
			flash_strb_suspend: flash_strb_suspend {
				drive-strength = <2>;
				bias-disable;
				output-low;
			};
		};

		lcd_rst_msm_n {
			qcom,pins = <&gp 25>;
			qcom,pin-func = <0>;
			qcom,num-grp-pins = <1>;
			label = "lcd_rst_msm_n";
			lcd_rst_msm_n_default: lcd_rst_msm_n_default {
				drive-strength = <2>;
				bias-disable;
				output-low;
			};
			lcd_rst_msm_n_active: lcd_rst_msm_n_active {
				drive-strength = <2>;
				bias-disable;
				output-high;/*@OEMDISPLAY@ MOD*/
			};
			lcd_rst_msm_n_suspend: lcd_rst_msm_n_suspend {
				drive-strength = <2>;
				bias-disable;
				output-low;
			};
		};

		lcd_det_n {
			qcom,pins = <&gp 31>;
			qcom,pin-func = <0>;
			qcom,num-grp-pins = <1>;
			label = "lcd_det_n";
			lcd_det_n_default: lcd_det_n_default {
				drive-strength = <2>;
				bias-pull-up;
				input-debounce = <0>;
			};
			lcd_det_n_active: lcd_det_n_active {
				drive-strength = <2>;
				bias-pull-up;
				input-debounce = <0>;
			};
			lcd_det_n_suspend: lcd_det_n_suspend {
				drive-strength = <2>;
				bias-pull-up;
				input-debounce = <0>;
			};
			lcd_det_n_det_active1: lcd_det_n_det_active1 {
				drive-strength = <2>;
				bias-pull-up;
				input-debounce = <0>;
			};
			lcd_det_n_det_active2: lcd_det_n_det_active2 {
				drive-strength = <2>;
				bias-pull-down;
				input-debounce = <0>;
			};
		};

		lcd_id0 {
			qcom,pins = <&gp 33>;
			qcom,pin-func = <0>;
			qcom,num-grp-pins = <1>;
			label = "lcd_id0";
			lcd_id0_active1: lcd_id0_active1 {
				drive-strength = <2>;
				bias-pull-up;
				input-debounce = <0>;
			};
			lcd_id0_active2: lcd_id0_active2 {
				drive-strength = <2>;
				bias-disable;
				input-debounce = <0>;
			};
		};

		lcd_id1 {
			qcom,pins = <&gp 69>;
			qcom,pin-func = <0>;
			qcom,num-grp-pins = <1>;
			label = "lcd_id1";
			lcd_id1_active1: lcd_id1_active1 {
				drive-strength = <2>;
				bias-pull-up;
				input-debounce = <0>;
			};
			lcd_id1_active2: lcd_id1_active2 {
				drive-strength = <2>;
				bias-disable;
				input-debounce = <0>;
			};
		};

		flash_resetb {
			qcom,pins = <&gp 36>;
			qcom,pin-func = <0>;
			qcom,num-grp-pins = <1>;
			label = "flash_resetb";
			flash_resetb_default: flash_resetb_default {
				drive-strength = <2>;
				bias-disable;
				output-low;
			};
			flash_resetb_active: flash_resetb_active {
				drive-strength = <2>;
				bias-disable;
				output-low;
			};
			flash_resetb_suspend: flash_resetb_suspend {
				drive-strength = <2>;
				bias-disable;
				output-low;
			};
		};

		forced_usb_boot {
			qcom,pins = <&gp 37>;
			qcom,pin-func = <0>;
			qcom,num-grp-pins = <1>;
			label = "forced_usb_boot";
			forced_usb_boot_default: forced_usb_boot_default {
				drive-strength = <2>;
				bias-pull-down;
				input-debounce = <0>;
			};
			forced_usb_boot_active: forced_usb_boot_active {
				drive-strength = <2>;
				bias-pull-down;
				input-debounce = <0>;
			};
			forced_usb_boot_suspend: forced_usb_boot_suspend {
				drive-strength = <2>;
				bias-pull-down;
				input-debounce = <0>;
			};
		};

		sd_card_det_n {
			qcom,pins = <&gp 38>;
			qcom,pin-func = <0>;
			qcom,num-grp-pins = <1>;
			label = "sd_card_det_n";
			sd_card_det_n_default: sd_card_det_n_default {
				drive-strength = <2>;
				bias-disable;
				input-debounce = <0>;
			};
			sd_card_det_n_active: sd_card_det_n_active {
				drive-strength = <2>;
				bias-disable;
				input-debounce = <0>;
			};
			sd_card_det_n_suspend: sd_card_det_n_suspend {
				drive-strength = <2>;
				bias-disable;
				input-debounce = <0>;
			};
		};

		fm_ssbi {
			qcom,pins = <&gp 45>;
			qcom,pin-func = <1>;
			qcom,num-grp-pins = <1>;
			label = "fm_ssbi";
			fm_ssbi_default: fm_ssbi_default {
				drive-strength = <2>;
				bias-disable;
				input-debounce = <0>;
			};
			fm_ssbi_active: fm_ssbi_active {
				drive-strength = <2>;
				bias-disable;
				input-debounce = <0>;
			};
			fm_ssbi_suspend: fm_ssbi_suspend {
				drive-strength = <2>;
				bias-disable;
				input-debounce = <0>;
			};
		};
		fm_data {
			qcom,pins = <&gp 46>;
			qcom,pin-func = <1>;
			qcom,num-grp-pins = <1>;
			label = "fm_data";
			fm_data_default: fm_data_default {
				drive-strength = <2>;
				bias-disable;
				input-debounce = <0>;
			};
			fm_data_active: fm_data_active {
				drive-strength = <2>;
				bias-disable;
				input-debounce = <0>;
			};
			fm_data_suspend: fm_data_suspend {
				drive-strength = <2>;
				bias-disable;
				input-debounce = <0>;
			};
		};

		uim_det {
			qcom,pins = <&gp 60>;
			qcom,pin-func = <0>;
			qcom,num-grp-pins = <1>;
			label = "uim_det";
			uim_det_default: uim_det_default {
				drive-strength = <2>;
				bias-disable;
				input-debounce = <0>;
			};
			uim_det_active: uim_det_active {
				drive-strength = <2>;
				bias-disable;
				input-debounce = <0>;
			};
			uim_det_suspend: uim_det_suspend {
				drive-strength = <2>;
				bias-disable;
				input-debounce = <0>;
			};
		};
		uim_batt_alm_gpio_1 {
			qcom,pins = <&gp 61>;
			qcom,pin-func = <0>;
			qcom,num-grp-pins = <1>;
			label = "uim_batt_alm_gpio_1";
			uim_batt_alm_gpio_1_default: uim_batt_alm_gpio_1_default {
				drive-strength = <2>;
				bias-pull-down;
				input-debounce = <0>;
			};
			uim_batt_alm_gpio_1_active: uim_batt_alm_gpio_1_active {
				drive-strength = <2>;
				bias-pull-down;
				input-debounce = <0>;
			};
			uim_batt_alm_gpio_1_suspend: uim_batt_alm_gpio_1_suspend {
				drive-strength = <2>;
				bias-pull-down;
				input-debounce = <0>;
			};
		};

		ant_tune {
			qcom,pins = <&gp 79>, <&gp 85>, <&gp 93>;
			qcom,pin-func = <1>;
			qcom,num-grp-pins = <3>;
			label = "ant_tune";
			ant_tune_default: ant_tune_default {
				drive-strength = <2>;
				bias-disable;
				output-low;
			};
			ant_tune_active: ant_tune_active {
				drive-strength = <2>;
				bias-disable;
				output-low;
			};
			ant_tune_suspend: ant_tune_suspend {
				drive-strength = <2>;
				bias-disable;
				output-low;
			};
		};

		wdog_disable {
			qcom,pins = <&gp 80>;
			qcom,pin-func = <0>;
			qcom,num-grp-pins = <1>;
			label = "wdog_disable";
			wdog_disable_default: wdog_disable_default {
				drive-strength = <2>;
				bias-pull-down;
				input-debounce = <0>;
			};
			wdog_disable_active: wdog_disable_active {
				drive-strength = <2>;
				bias-pull-down;
				input-debounce = <0>;
			};
			wdog_disable_suspend: wdog_disable_n_suspend {
				drive-strength = <2>;
				bias-pull-down;
				input-debounce = <0>;
			};
		};

		ext_gps_lna_en {
			qcom,pins = <&gp 96>;
			qcom,pin-func = <0>;
			qcom,num-grp-pins = <1>;
			label = "ext_gps_lna_en";
			ext_gps_lna_en_default: ext_gps_lna_en_default {
				drive-strength = <2>;
				bias-disable;
				output-low;
			};
			ext_gps_lna_en_active: ext_gps_lna_en_active {
				drive-strength = <2>;
				bias-disable;
				output-low;
			};
			ext_gps_lna_en_suspend: ext_gps_lna_en_suspend {
				drive-strength = <2>;
				bias-disable;
				output-low;
			};
		};

		led_r_cnt {
			qcom,pins = <&gp 97>;
			qcom,pin-func = <0>;
			qcom,num-grp-pins = <1>;
			label = "ant_tune";
			led_r_cnt_default: led_r_cnt_default {
				drive-strength = <2>;
				bias-disable;
				output-low;
			};
			led_r_cnt_active: led_r_cnt_active {
				drive-strength = <2>;
				bias-disable;
				output-low;
			};
			led_r_cnt_suspend: led_r_cnt_suspend {
				drive-strength = <2>;
				bias-disable;
				output-low;
			};
		};

		lcd_bl_drv_en {
			qcom,pins = <&gp 98>;
			qcom,pin-func = <0>;
			qcom,num-grp-pins = <1>;
			label = "lcd_bl_drv_en";
			lcd_bl_drv_en_default: lcd_bl_drv_en_default {
				drive-strength = <2>;
				bias-disable;
				output-low;
			};
			lcd_bl_drv_en_active: lcd_bl_drv_en_active {
				drive-strength = <2>;
				bias-disable;
				output-low;
			};
			lcd_bl_drv_en_suspend: lcd_bl_drv_en_suspend {
				drive-strength = <2>;
				bias-disable;
				output-low;
			};
		};

		vsensor_en {
			qcom,pins = <&gp 109>;
			qcom,pin-func = <0>;
			qcom,num-grp-pins = <1>;
			label = "vsensor_en";
			vsensor_en_default: vsensor_en_default {
				drive-strength = <2>;
				bias-disable;
				output-low;
			};
			vsensor_en_active: vsensor_en_active {
				drive-strength = <2>;
				bias-disable;
				output-low;
			};
			vsensor_en_suspend: vsensor_en_suspend {
				drive-strength = <2>;
				bias-disable;
				output-high;
			};
		};

		cam_main_id {
			qcom,pins = <&gp 110>;
			qcom,pin-func = <0>;
			qcom,num-grp-pins = <1>;
			label = "cam_main_id";
			cam_main_id_default: cam_main_id_default {
				drive-strength = <2>;
				bias-pull-up;
				input-debounce = <0>;
			};
			cam_main_id_active: cam_main_id_active {
				drive-strength = <2>;
				bias-pull-up;
				input-debounce = <0>;
			};
			cam_main_id_suspend: cam_main_id_suspend {
				drive-strength = <2>;
				bias-pull-down; /* PULL DOWN */
				input-debounce = <0>;
			};
		};

		proximity_int_n {
			qcom,pins = <&gp 113>;
			qcom,pin-func = <0>;
			qcom,num-grp-pins = <1>;
			label = "proximity_int_n";
			proximity_int_n_default: proximity_int_n_default {
				drive-strength = <2>;
				bias-pull-up;
				input-debounce = <0>;
			};
			proximity_int_n_active: proximity_int_n_active {
				drive-strength = <2>;
				bias-pull-up;
				input-debounce = <0>;
			};
			proximity_int_n_suspend: proximity_int_n_suspend {
				drive-strength = <2>;
				bias-pull-up;
				input-debounce = <0>;
			};
		};

		vcamd_en {
			qcom,pins = <&gp 114>;
			qcom,pin-func = <0>;
			qcom,num-grp-pins = <1>;
			label = "vcamd_en";
			vcamd_en_default: vcamd_en_default {
				drive-strength = <2>;
				bias-disable;
				output-low;
			};
			vcamd_en_active: vcamd_en_active {
				drive-strength = <2>;
				bias-disable;
				output-low;
			};
			vcamd_en_suspend: vcamd_en_suspend {
				drive-strength = <2>;
				bias-disable;
				output-low;
			};
		};

		hkadc_kar_wake_out {
			qcom,pins = <&gp 115>;
			qcom,pin-func = <0>;
			qcom,num-grp-pins = <1>;
			label = "hkadc_kar_wake_out";
			hkadc_kar_wake_out_default: hkadc_kar_wake_out_default {
				drive-strength = <2>;
				bias-disable;
				output-low;
			};
			hkadc_kar_wake_out_active: hkadc_kar_wake_out_active {
				drive-strength = <2>;
				bias-disable;
				output-low;
			};
			hkadc_kar_wake_out_suspend: hkadc_kar_wake_out_suspend {
				drive-strength = <2>;
				bias-disable;
				output-low;
			};
		};

		cam_sub_id {
			qcom,pins = <&gp 117>;
			qcom,pin-func = <0>;
			qcom,num-grp-pins = <1>;
			label = "cam_sub_id";
			cam_sub_id_default: cam_sub_id_default {
				drive-strength = <2>;
				bias-pull-up;
				input-debounce = <0>;
			};
			cam_sub_id_active: cam_sub_id_active {
				drive-strength = <2>;
				bias-pull-up;
				input-debounce = <0>;
			};
			cam_sub_id_suspend: cam_sub_id_suspend {
				drive-strength = <2>;
				bias-pull-down; /* PULL DOWN */
				input-debounce = <0>;
			};
		};

		uim_det_n {
			qcom,pins = <&gp 118>;
			qcom,pin-func = <0>;
			qcom,num-grp-pins = <1>;
			label = "uim_det_n";
			uim_det_n_default: uim_det_n_default {
				drive-strength = <2>;
				bias-disable;
				input-debounce = <0>;
			};
			uim_det_n_active: uim_det_n_active {
				drive-strength = <2>;
				bias-disable;
				input-debounce = <0>;
			};
			uim_det_n_suspend: uim_det_n_suspend {
				drive-strength = <2>;
				bias-disable;
				input-debounce = <0>;
			};
		};

		hkadc_kar_wake_in {
			qcom,pins = <&gp 120>;
			qcom,pin-func = <0>;
			qcom,num-grp-pins = <1>;
			label = "hkadc_kar_wake_in";
			hkadc_kar_wake_in_default: hkadc_kar_wake_in_default {
				drive-strength = <2>;
				bias-disable;
				input-debounce = <0>;
			};
			hkadc_kar_wake_in_active: hkadc_kar_wake_in_active {
				drive-strength = <2>;
				bias-disable;
				input-debounce = <0>;
			};
			hkadc_kar_wake_in_suspend: hkadc_kar_wake_in_suspend {
				drive-strength = <2>;
				bias-disable;
				input-debounce = <0>;
			};
		};
	};
};
